# ATA5790N device description
Architecture: AVR8; Family: megaAVR
Registers are 8-bit, access not given, no defined reset value unless marked. A register's access mark holds for its fields unless they carry their own. Offsets are from the block's base; [hi:lo] are bit positions.

## TIMER_COUNTER_0
Instances: TIMER_COUNTER_0 0x00
0x39 T0IFR — Timer0 Interrupt Flag Register
  [0] T0F — Timer 0 Flag Bit
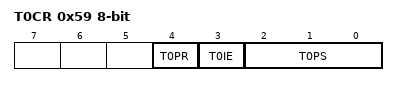
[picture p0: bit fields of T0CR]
0x59 T0CR — Timer 0 Control Register
  [4] T0PR — Timer 0 Prescaler Reset Bit
  [3] T0IE — Timer 0 Interrupt Enable Bit
  [2:0] T0PS — Timer 0 Prescaler Select Bits

## TIMER_COUNTER_1
Instances: TIMER_COUNTER_1 0x00
0x3A T1IFR — Timer1 Interrupt Flag Register
  [0] T1F — Timer 1 Flag Bit
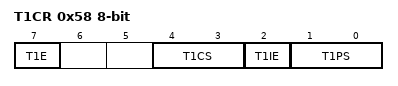
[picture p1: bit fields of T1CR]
0x58 T1CR — Timer 1 Control Register
  [7] T1E — Timer 1 Enable Bit
  [4:3] T1CS — Timer 1 Clock Select Bits
  [2] T1IE — Timer 1 Interrupt Enable Bit
  [1:0] T1PS — Timer 1 Prescaler Select Bits

## TIMER_COUNTER_2
Instances: TIMER_COUNTER_2 0x00
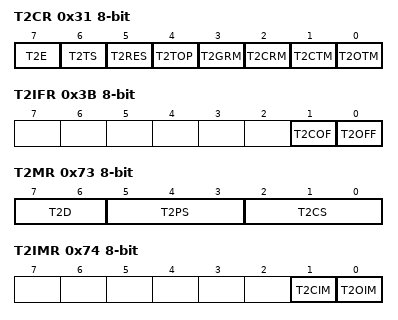
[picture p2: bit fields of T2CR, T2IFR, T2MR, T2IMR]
0x31 T2CR — Timer 2 Control Register
  [7] T2E — Timer 2 Enable Bit
  [6] T2TS — Timer 2 Toggle with Start Bit
  [5] T2RES — Timer 2 Reset Bit
  [4] T2TOP — Toggle Output Preset Bit
  [3] T2GRM — Timer 2 Gap Reset Mask Bit
  [2] T2CRM — Timer2 Compare Reset Mask Bit
  [1] T2CTM — Timer 2 Compare Toggle Mask Bit
  [0] T2OTM — Timer 2 Overflow Toggle Mask Bit
0x3B T2IFR — Timer2 Interrupt Flag Register
  [1] T2COF — Timer 2 Compare Flag Bit
  [0] T2OFF — Timer 2 Overflow Flag Bit
0x70 T2CNT — Timer 2 Counter Register
0x71 T2COR — Timer2 Compare Register
0x73 T2MR — Timer 2 Mode Register
  [7:6] T2D — Timer 2 Duty Cycle Bits
  [5:3] T2PS — Timer 2 Prescaler Select Bits
  [2:0] T2CS — Timer 2 Clock Select Bits
0x74 T2IMR — Timer 2 Interrupt Mask Register
  [1] T2CIM — Timer 2 Compare Interrupt Mask Bit
  [0] T2OIM — Timer 2 Overflow Interrupt Mask Bit

## TIMER_COUNTER_3
Instances: TIMER_COUNTER_3 0x00
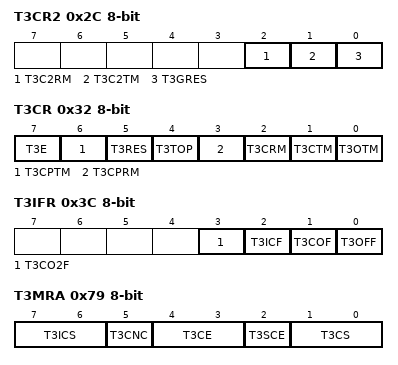
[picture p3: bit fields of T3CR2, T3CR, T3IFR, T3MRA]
0x2C T3CR2 — Timer3 Control Register 2
  [2] T3C2RM — Timer 3 Compare 2 Reset Mask bit
  [1] T3C2TM — Timer 3 Compare 2 Toggle Mask bit
  [0] T3GRES — Timer 3 Global Reset Bit
0x32 T3CR — Timer 3 Control Register
  [7] T3E — Timer 3 Enable Bit
  [6] T3CPTM — Timer 3 Capture Toggle Mask Bit
  [5] T3RES — Timer 3 Reset Bit
  [4] T3TOP — Timer 3 Toggle Output Preset Bit
  [3] T3CPRM — Timer 3 Capture Reset Mask Bit
  [2] T3CRM — Timer3 Compare Reset Mask Bit
  [1] T3CTM — Timer 3 Compare Toggle Mask Bit
  [0] T3OTM — Timer 3 Overflow Toggle Mask Bit
0x3C T3IFR — Timer3 Interrupt Flag Register
  [3] T3CO2F — Timer3 Compare 2 Flag bit
  [2] T3ICF — Timer3 Input Capture Flag bit
  [1] T3COF — Timer3 Compare Flag bit
  [0] T3OFF — Timer3 OverFlow Flag bit
0x75 T3CO2R — Timer3 COmpare2 Register
0x76 T3CNT — Timer3 Counter Register
0x77 T3COR — Timer3 COmpare Register
0x78 T3ICR — Timer3 Input Capture Register
0x79 T3MRA — Timer 3 Mode Register A
  [7:6] T3ICS — Timer 3 Input Capture Select Bits
  [5] T3CNC — Timer 3 Input Capture Noise Canceler Bit
  [4:3] T3CE — Timer 3 Capture Edge select Bits
  [2] T3SCE — Timer 3 Software Capture Enable Bit
  [1:0] T3CS — Timer 3 Clock Select Bits
0x7A T3MRB — Timer 3 Mode Register B
  [2:0] T3PS — Timer 3 Prescaler Select Bits
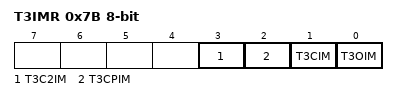
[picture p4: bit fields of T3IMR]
0x7B T3IMR — Timer3 Interrupt Mask Register
  [3] T3C2IM — Timer3 Compare 2 Interrupt Mask bit
  [2] T3CPIM — Timer3 Capture Interrupt Mask bit
  [1] T3CIM — Timer3 Compare Interrupt Mask bit
  [0] T3OIM — Timer3 Overflow Interrupt Mask bit

## RTC_TIMER
Instances: RTC_TIMER 0x00
0x9E RTCCR — Real-Time Clock Control Register
  [0] RTCR — Real-Time Counter Reset Bit
0x9F RTCDR — Real Time Clock Data Register

## WDT — Watchdog Timer
Instances: WDT 0x00
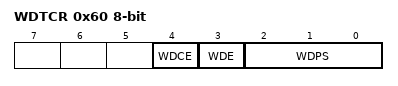
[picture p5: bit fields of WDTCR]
0x60 WDTCR — Watchdog Timer Control Register
  [4] WDCE — Watchdog Change Enable
  [3] WDE — Watch Dog Enable
  [2:0] WDPS — Watch Dog Timer Prescaler Select bits

## CRC
Instances: CRC 0x00
0xAC CRCPOL — CRC Polynomial Data Register
0xAD CRCDR — CRC Data Register
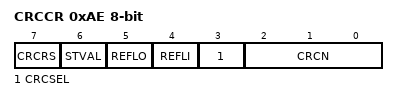
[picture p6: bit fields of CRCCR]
0xAE CRCCR — CRC Control Register
  [7] CRCRS — CRC Reset Bit
  [6] STVAL — Start VALue Bit
  [5] REFLO — Reflect Output Data Bit
  [4] REFLI — Reflect Input Data Bit
  [3] CRCSEL — CRC Mode Select Bit
  [2:0] CRCN — Partial CRC Computation Bits
0xAF CRCSR — CRC Status Register
  [0] CRCBF — CRC Busy Flag

## PORTC
Instances: PORTC 0x00
0x26 PINC — Port C Input Pins
0x27 DDRC — Port C Data Direction Register
0x28 PORTC — Port C Data Register
